# STM32F072x register map
Vendor: STM>; File version: 1.0
Registers are 32-bit, read-write, reset 0x0 unless marked. A register's access mark holds for its fields unless they carry their own. Offsets are from the block's base; [hi:lo] are bit positions; {n}, {i} and the like mark numbered series.

## Flash
Base 0x40022000
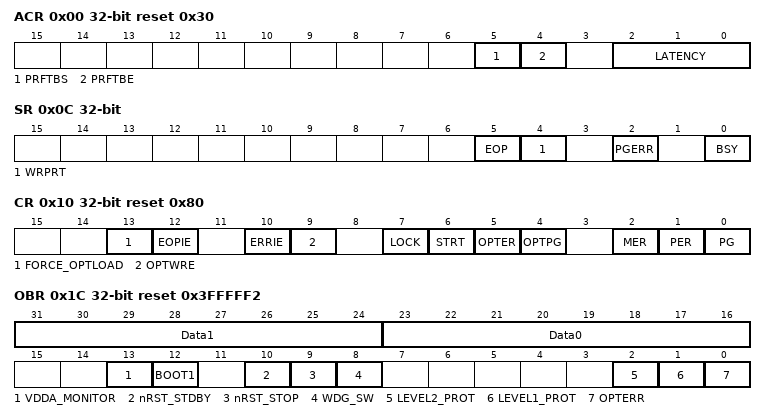
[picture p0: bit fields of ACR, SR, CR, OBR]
0x00 ACR access per field reset 0x30 — Flash access control register
  [5] PRFTBS ro, [4] PRFTBE rw, [2:0] LATENCY rw
0x04 KEYR wo — Flash key register
  [31:0] FKEYR — Flash Key
0x08 OPTKEYR wo — Flash option key register
  [31:0] OPTKEYR — Option byte key
0x0C SR access per field — Flash status register
  [5] EOP rw — End of operation
  [4] WRPRT rw — Write protection error
  [2] PGERR rw — Programming error
  [0] BSY ro — Busy
0x10 CR reset 0x80 — Flash control register
  [13] FORCE_OPTLOAD — Force option byte loading
  [12] EOPIE — End of operation interrupt enable
  [10] ERRIE — Error interrupt enable
  [9] OPTWRE — Option bytes write enable
  [7] LOCK
  [6] STRT — Start
  [5] OPTER — Option byte erase
  [4] OPTPG — Option byte programming
  [2] MER — Mass erase
  [1] PER — Page erase
  [0] PG — Programming
0x14 AR wo — Flash address register
  [31:0] FAR — Flash address
0x1C OBR ro reset 0x3FFFFF2 — Option byte register
  [31:24] Data1
  [23:16] Data0
  [13] VDDA_MONITOR
  [12] BOOT1
  [10] nRST_STDBY
  [9] nRST_STOP
  [8] WDG_SW
  [2] LEVEL2_PROT — Level 2 protection status
  [1] LEVEL1_PROT — Level 1 protection status
  [0] OPTERR — Option byte error
0x20 WRPR ro reset 0xFFFFFFFF — Write protection register
  [31:0] WRP — Write protect

## DBGMCU — Debug support
Base 0x40015800
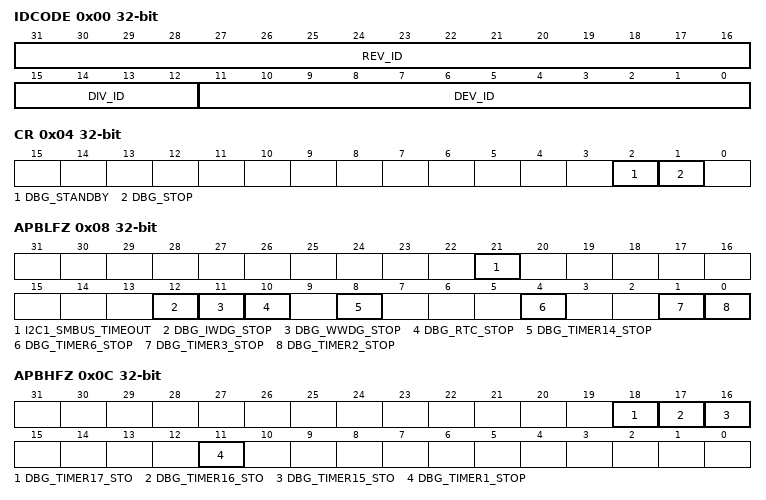
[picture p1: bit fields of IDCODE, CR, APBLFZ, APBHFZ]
0x00 IDCODE ro — MCU Device ID Code Register
  [31:16] REV_ID — Revision Identifier
  [15:12] DIV_ID — Division Identifier
  [11:0] DEV_ID — Device Identifier
0x04 CR — Debug MCU Configuration Register
  [2] DBG_STANDBY — Debug Standby Mode
  [1] DBG_STOP — Debug Stop Mode
0x08 APBLFZ — APB Low Freeze Register
  [21] I2C1_SMBUS_TIMEOUT — SMBUS timeout mode stopped when Core is halted
  [12] DBG_IWDG_STOP — Debug Independent Wachdog stopped when Core is halted
  [11] DBG_WWDG_STOP — Debug Window Wachdog stopped when Core is halted
  [10] DBG_RTC_STOP — Debug RTC stopped when Core is halted
  [8] DBG_TIMER14_STOP — Debug Timer 14 stopped when Core is halted
  [4] DBG_TIMER6_STOP — Debug Timer 6 stopped when Core is halted
  [1] DBG_TIMER3_STOP — Debug Timer 3 stopped when Core is halted
  [0] DBG_TIMER2_STOP — Debug Timer 2 stopped when Core is halted
0x0C APBHFZ — APB High Freeze Register
  [18] DBG_TIMER17_STO — Debug Timer 17 stopped when Core is halted
  [17] DBG_TIMER16_STO — Debug Timer 16 stopped when Core is halted
  [16] DBG_TIMER15_STO — Debug Timer 15 stopped when Core is halted
  [11] DBG_TIMER1_STOP — Debug Timer 1 stopped when Core is halted

## USB — Universal serial bus full-speed device interface
Base 0x40005C00
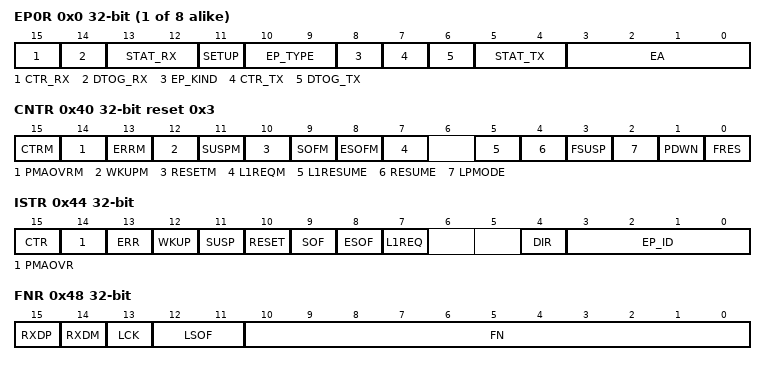
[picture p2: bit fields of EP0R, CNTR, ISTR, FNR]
{0x0+4i} EP{i}R (i=0..7) — endpoint {i} register
  [15] CTR_RX — Correct transfer for reception
  [14] DTOG_RX — Data Toggle, for reception transfers
  [13:12] STAT_RX — Status bits, for reception transfers
  [11] SETUP — Setup transaction completed
  [10:9] EP_TYPE — Endpoint type
  [8] EP_KIND — Endpoint kind
  [7] CTR_TX — Correct Transfer for transmission
  [6] DTOG_TX — Data Toggle, for transmission transfers
  [5:4] STAT_TX — Status bits, for transmission transfers
  [3:0] EA — Endpoint address
0x40 CNTR reset 0x3 — control register
  [15] CTRM — Correct transfer interrupt mask
  [14] PMAOVRM — Packet memory area over / underrun interrupt mask
  [13] ERRM — Error interrupt mask
  [12] WKUPM — Wakeup interrupt mask
  [11] SUSPM — Suspend mode interrupt mask
  [10] RESETM — USB reset interrupt mask
  [9] SOFM — Start of frame interrupt mask
  [8] ESOFM — Expected start of frame interrupt mask
  [7] L1REQM — LPM L1 state request interrupt mask
  [5] L1RESUME — LPM L1 Resume request
  [4] RESUME — Resume request
  [3] FSUSP — Force suspend
  [2] LPMODE — Low-power mode
  [1] PDWN — Power down
  [0] FRES — Force USB Reset
0x44 ISTR access per field — interrupt status register
  [15] CTR ro — Correct transfer
  [14] PMAOVR rw — Packet memory area over / underrun
  [13] ERR rw — Error
  [12] WKUP rw — Wakeup
  [11] SUSP rw — Suspend mode request
  [10] RESET rw — reset request
  [9] SOF rw — start of frame
  [8] ESOF rw — Expected start frame
  [7] L1REQ rw — LPM L1 state request
  [4] DIR ro — Direction of transaction
  [3:0] EP_ID ro — Endpoint Identifier
0x48 FNR ro — frame number register
  [15] RXDP — Receive data + line status
  [14] RXDM — Receive data - line status
  [13] LCK — Locked
  [12:11] LSOF — Lost SOF
  [10:0] FN — Frame number
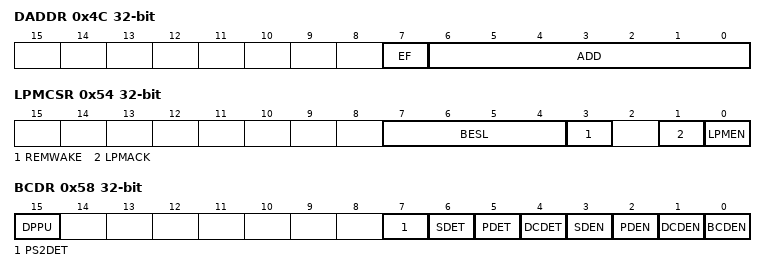
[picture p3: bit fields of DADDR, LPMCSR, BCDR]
0x4C DADDR — device address
  [7] EF — Enable function
  [6:0] ADD — Device address
0x50 BTABLE — Buffer table address
  [15:3] BTABLE — Buffer table
0x54 LPMCSR access per field — LPM control and status register
  [7:4] BESL ro — BESL value
  [3] REMWAKE ro — bRemoteWake value
  [1] LPMACK rw — LPM Token acknowledge enable
  [0] LPMEN rw — LPM support enable
0x58 BCDR access per field — Battery charging detector
  [15] DPPU rw — DP pull-up control
  [7] PS2DET ro — DM pull-up detection status
  [6] SDET ro — Secondary detection (SD) status
  [5] PDET ro — Primary detection (PD) status
  [4] DCDET ro — Data contact detection (DCD) status
  [3] SDEN rw — Secondary detection (SD) mode enable
  [2] PDEN rw — Primary detection (PD) mode enable
  [1] DCDEN rw — Data contact detection (DCD) mode enable
  [0] BCDEN rw — Battery charging detector (BCD) enable
